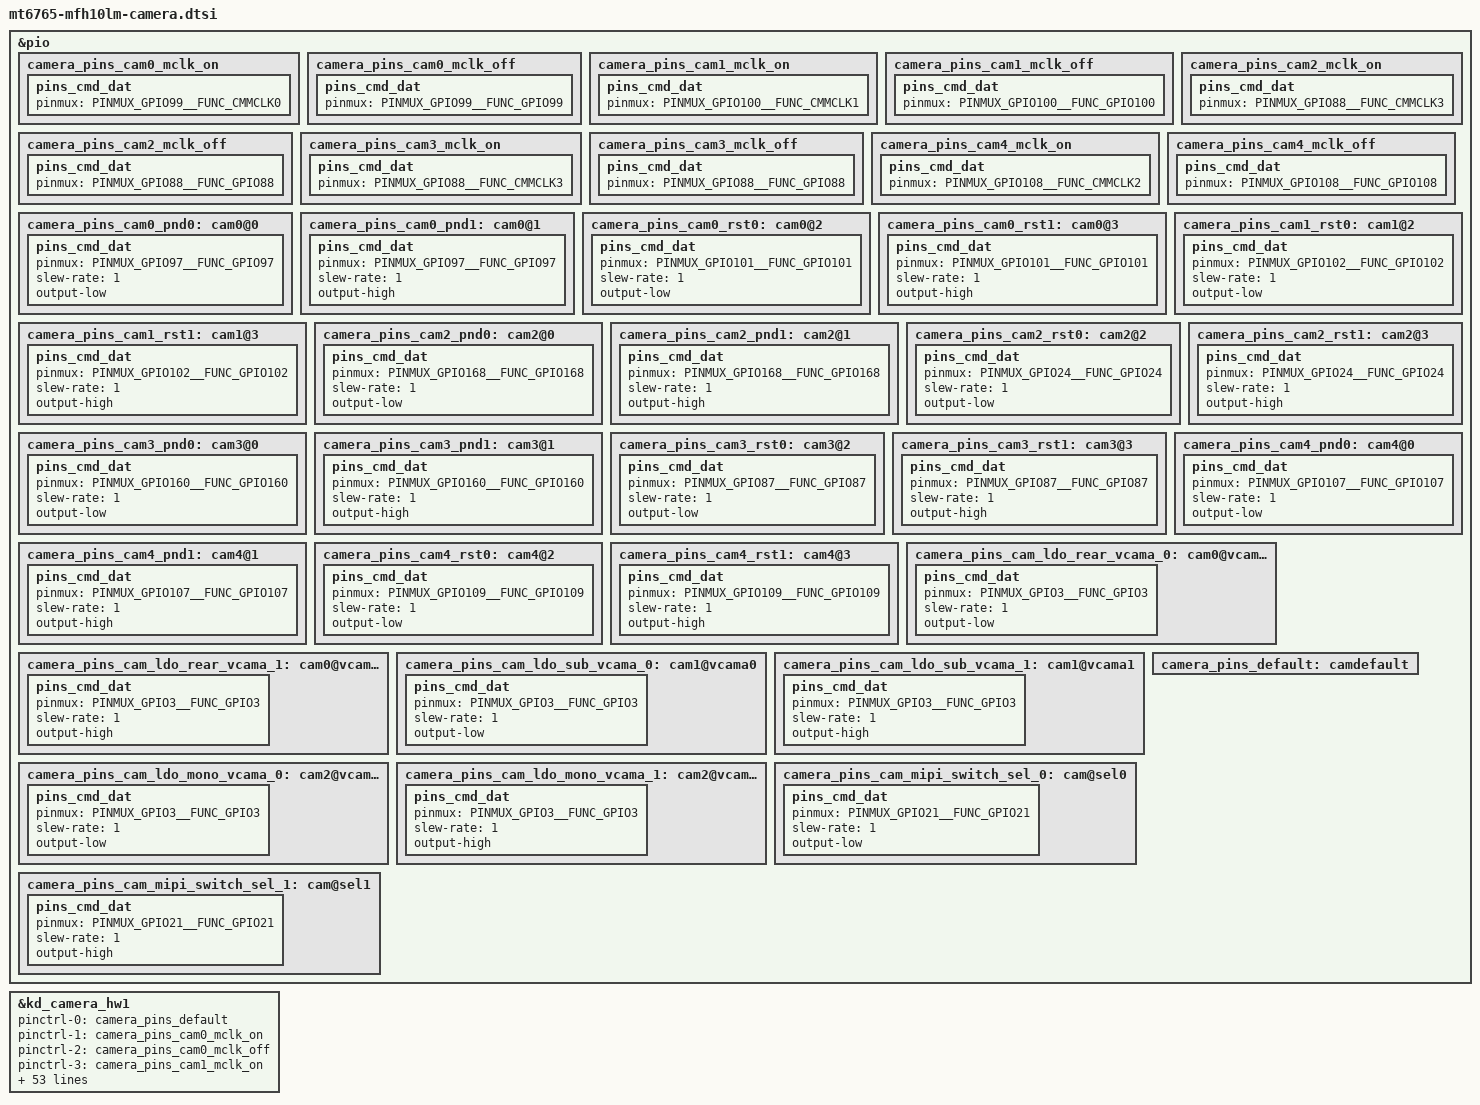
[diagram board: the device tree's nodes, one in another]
/*
 * Copyright (c) 2019 MediaTek Inc.
 *
 * This program is free software; you can redistribute it and/or modify
 * it under the terms of the GNU General Public License version 2 as
 * published by the Free Software Foundation.
 *
 * This program is distributed in the hope that it will be useful,
 * but WITHOUT ANY WARRANTY; without even the implied warranty of
 * MERCHANTABILITY or FITNESS FOR A PARTICULAR PURPOSE.  See the
 * GNU General Public License for more details.
 */
/* CAMERA GPIO standardization */
&pio {
	camera_pins_cam0_mclk_on: camera_pins_cam0_mclk_on {
		pins_cmd_dat {
			pinmux = <PINMUX_GPIO99__FUNC_CMMCLK0>;
		};
	};
	camera_pins_cam0_mclk_off: camera_pins_cam0_mclk_off {
		pins_cmd_dat {
			pinmux = <PINMUX_GPIO99__FUNC_GPIO99>;
		};
	};
	camera_pins_cam1_mclk_on: camera_pins_cam1_mclk_on {
		pins_cmd_dat {
			pinmux = <PINMUX_GPIO100__FUNC_CMMCLK1>;
		};
	};
	camera_pins_cam1_mclk_off: camera_pins_cam1_mclk_off {
		pins_cmd_dat {
			pinmux = <PINMUX_GPIO100__FUNC_GPIO100>;
		};
	};
	camera_pins_cam2_mclk_on: camera_pins_cam2_mclk_on {
		pins_cmd_dat {
			pinmux = <PINMUX_GPIO88__FUNC_CMMCLK3>;
		};
	};
	camera_pins_cam2_mclk_off: camera_pins_cam2_mclk_off {
		pins_cmd_dat {
			pinmux = <PINMUX_GPIO88__FUNC_GPIO88>;
		};
	};
	camera_pins_cam3_mclk_on: camera_pins_cam3_mclk_on {
		pins_cmd_dat {
			pinmux = <PINMUX_GPIO88__FUNC_CMMCLK3>;
		};
	};
	camera_pins_cam3_mclk_off: camera_pins_cam3_mclk_off {
		pins_cmd_dat {
			pinmux = <PINMUX_GPIO88__FUNC_GPIO88>;
		};
	};
	camera_pins_cam4_mclk_on: camera_pins_cam4_mclk_on {
		pins_cmd_dat {
			pinmux = <PINMUX_GPIO108__FUNC_CMMCLK2>;
		};
	};
	camera_pins_cam4_mclk_off: camera_pins_cam4_mclk_off {
		pins_cmd_dat {
			pinmux = <PINMUX_GPIO108__FUNC_GPIO108>;
		};
	};
	camera_pins_cam0_pnd0: cam0@0 {
		pins_cmd_dat {
			pinmux = <PINMUX_GPIO97__FUNC_GPIO97>;
			slew-rate = <1>;
			output-low;
		};
	};
	camera_pins_cam0_pnd1: cam0@1 {
		pins_cmd_dat {
			pinmux = <PINMUX_GPIO97__FUNC_GPIO97>;
			slew-rate = <1>;
			output-high;
		};
	};
	camera_pins_cam0_rst0: cam0@2 {
		pins_cmd_dat {
			pinmux = <PINMUX_GPIO101__FUNC_GPIO101>;
			slew-rate = <1>;
			output-low;
		};
	};
	camera_pins_cam0_rst1: cam0@3 {
		pins_cmd_dat {
			pinmux = <PINMUX_GPIO101__FUNC_GPIO101>;
			slew-rate = <1>;
			output-high;
		};
	};
	camera_pins_cam1_rst0: cam1@2 {
		pins_cmd_dat {
			pinmux = <PINMUX_GPIO102__FUNC_GPIO102>;
			slew-rate = <1>;
			output-low;
		};
	};
	camera_pins_cam1_rst1: cam1@3 {
		pins_cmd_dat {
			pinmux = <PINMUX_GPIO102__FUNC_GPIO102>;
			slew-rate = <1>;
			output-high;
		};
	};
	camera_pins_cam2_pnd0: cam2@0 {
		pins_cmd_dat {
			pinmux = <PINMUX_GPIO168__FUNC_GPIO168>;
			slew-rate = <1>;
			output-low;
		};
	};
	camera_pins_cam2_pnd1: cam2@1 {
		pins_cmd_dat {
			pinmux = <PINMUX_GPIO168__FUNC_GPIO168>;
			slew-rate = <1>;
			output-high;
		};
	};
	camera_pins_cam2_rst0: cam2@2 {
		pins_cmd_dat {
			pinmux = <PINMUX_GPIO24__FUNC_GPIO24>;
			slew-rate = <1>;
			output-low;
		};
	};
	camera_pins_cam2_rst1: cam2@3 {
		pins_cmd_dat {
			pinmux = <PINMUX_GPIO24__FUNC_GPIO24>;
			slew-rate = <1>;
			output-high;
		};
	};
	camera_pins_cam3_pnd0: cam3@0 {
		pins_cmd_dat {
			pinmux = <PINMUX_GPIO160__FUNC_GPIO160>;
			slew-rate = <1>;
			output-low;
		};
	};
	camera_pins_cam3_pnd1: cam3@1 {
		pins_cmd_dat {
			pinmux = <PINMUX_GPIO160__FUNC_GPIO160>;
			slew-rate = <1>;
			output-high;
		};
	};
	camera_pins_cam3_rst0: cam3@2 {
		pins_cmd_dat {
			pinmux = <PINMUX_GPIO87__FUNC_GPIO87>;
			slew-rate = <1>;
			output-low;
		};
	};
	camera_pins_cam3_rst1: cam3@3 {
		pins_cmd_dat {
			pinmux = <PINMUX_GPIO87__FUNC_GPIO87>;
			slew-rate = <1>;
			output-high;
		};
	};
	camera_pins_cam4_pnd0: cam4@0 {
		pins_cmd_dat {
			pinmux = <PINMUX_GPIO107__FUNC_GPIO107>;
			slew-rate = <1>;
			output-low;
		};
	};
	camera_pins_cam4_pnd1: cam4@1 {
		pins_cmd_dat {
			pinmux = <PINMUX_GPIO107__FUNC_GPIO107>;
			slew-rate = <1>;
			output-high;
		};
	};
	camera_pins_cam4_rst0: cam4@2 {
		pins_cmd_dat {
			pinmux = <PINMUX_GPIO109__FUNC_GPIO109>;
			slew-rate = <1>;
			output-low;
		};
	};
	camera_pins_cam4_rst1: cam4@3 {
		pins_cmd_dat {
			pinmux = <PINMUX_GPIO109__FUNC_GPIO109>;
			slew-rate = <1>;
			output-high;
		};
	};
	camera_pins_cam_ldo_rear_vcama_0: cam0@vcama0 {
		pins_cmd_dat {
			pinmux = <PINMUX_GPIO3__FUNC_GPIO3>;
			slew-rate = <1>;
			output-low;
		};
	};
	camera_pins_cam_ldo_rear_vcama_1: cam0@vcama1 {
		pins_cmd_dat {
			pinmux = <PINMUX_GPIO3__FUNC_GPIO3>;
			slew-rate = <1>;
			output-high;
		};
	};
	camera_pins_cam_ldo_sub_vcama_0: cam1@vcama0 {
		pins_cmd_dat {
			pinmux = <PINMUX_GPIO3__FUNC_GPIO3>;
			slew-rate = <1>;
			output-low;
		};
	};
	camera_pins_cam_ldo_sub_vcama_1: cam1@vcama1 {
		pins_cmd_dat {
			pinmux = <PINMUX_GPIO3__FUNC_GPIO3>;
			slew-rate = <1>;
			output-high;
		};
	};
	camera_pins_cam_ldo_mono_vcama_0: cam2@vcama0 {
		pins_cmd_dat {
			pinmux = <PINMUX_GPIO3__FUNC_GPIO3>;
			slew-rate = <1>;
			output-low;
		};
	};
	camera_pins_cam_ldo_mono_vcama_1: cam2@vcama1 {
		pins_cmd_dat {
			pinmux = <PINMUX_GPIO3__FUNC_GPIO3>;
			slew-rate = <1>;
			output-high;
		};
	};
	camera_pins_cam_mipi_switch_sel_0: cam@sel0 {
		pins_cmd_dat {
			pinmux = <PINMUX_GPIO21__FUNC_GPIO21>;
			slew-rate = <1>;
			output-low;
		};
	};
	camera_pins_cam_mipi_switch_sel_1: cam@sel1 {
		pins_cmd_dat {
			pinmux = <PINMUX_GPIO21__FUNC_GPIO21>;
			slew-rate = <1>;
			output-high;
		};
	};
	camera_pins_default: camdefault {
	};

};

&kd_camera_hw1 {
	pinctrl-names = "default",
			"cam0_mclk_on",
			"cam0_mclk_off",
			"cam1_mclk_on",
			"cam1_mclk_off",
			"cam2_mclk_on",
			"cam2_mclk_off",
			"cam3_mclk_on",
			"cam3_mclk_off",
			"cam4_mclk_on",
			"cam4_mclk_off",
			"cam0_pnd0",
			"cam0_pnd1",
			"cam0_rst0",
			"cam0_rst1",
			"cam1_rst0",
			"cam1_rst1",
			"cam2_pnd0",
			"cam2_pnd1",
			"cam2_rst0",
			"cam2_rst1",
			"cam3_pnd0",
			"cam3_pnd1",
			"cam3_rst0",
			"cam3_rst1",
			"cam4_pnd0",
			"cam4_pnd1",
			"cam4_rst0",
			"cam4_rst1",
			"cam0_vcama_on",
			"cam0_vcama_off",
			"cam1_vcama_on",
			"cam1_vcama_off",
			"cam2_vcama_on",
			"cam2_vcama_off",
			"cam_mipi_switch_sel_1",
			"cam_mipi_switch_sel_0";

	pinctrl-0 = <&camera_pins_default>;
	pinctrl-1 = <&camera_pins_cam0_mclk_on>;
	pinctrl-2 = <&camera_pins_cam0_mclk_off>;
	pinctrl-3 = <&camera_pins_cam1_mclk_on>;
	pinctrl-4 = <&camera_pins_cam1_mclk_off>;
	pinctrl-5 = <&camera_pins_cam2_mclk_on>;
	pinctrl-6 = <&camera_pins_cam2_mclk_off>;
	pinctrl-7 = <&camera_pins_cam3_mclk_on>;
	pinctrl-8 = <&camera_pins_cam3_mclk_off>;
	pinctrl-9 = <&camera_pins_cam4_mclk_on>;
	pinctrl-10 = <&camera_pins_cam4_mclk_off>;
	pinctrl-11 = <&camera_pins_cam0_pnd0>;
	pinctrl-12 = <&camera_pins_cam0_pnd1>;
	pinctrl-13 = <&camera_pins_cam0_rst0>;
	pinctrl-14 = <&camera_pins_cam0_rst1>;
	pinctrl-15 = <&camera_pins_cam1_rst0>;
	pinctrl-16 = <&camera_pins_cam1_rst1>;
	pinctrl-17 = <&camera_pins_cam2_pnd0>;
	pinctrl-18 = <&camera_pins_cam2_pnd1>;
	pinctrl-19 = <&camera_pins_cam2_rst0>;
	pinctrl-20 = <&camera_pins_cam2_rst1>;
	pinctrl-21 = <&camera_pins_cam3_pnd0>;
	pinctrl-22 = <&camera_pins_cam3_pnd1>;
	pinctrl-23 = <&camera_pins_cam3_rst0>;
	pinctrl-24 = <&camera_pins_cam3_rst1>;
	pinctrl-25 = <&camera_pins_cam4_pnd0>;
	pinctrl-26 = <&camera_pins_cam4_pnd1>;
	pinctrl-27 = <&camera_pins_cam4_rst0>;
	pinctrl-28 = <&camera_pins_cam4_rst1>;
	pinctrl-29 = <&camera_pins_cam_ldo_rear_vcama_1>;
	pinctrl-30 = <&camera_pins_cam_ldo_rear_vcama_0>;
	pinctrl-31 = <&camera_pins_cam_ldo_sub_vcama_1>;
	pinctrl-32 = <&camera_pins_cam_ldo_sub_vcama_0>;
	pinctrl-33 = <&camera_pins_cam_ldo_mono_vcama_1>;
	pinctrl-34 = <&camera_pins_cam_ldo_mono_vcama_0>;
	pinctrl-35 = <&camera_pins_cam_mipi_switch_sel_1>;
	pinctrl-36 = <&camera_pins_cam_mipi_switch_sel_0>;

	cam0_vcamd-supply = <&mt_pmic_vcamd_ldo_reg>;
	cam0_vcamio-supply = <&mt_pmic_vcamio_ldo_reg>;
	cam0_vcamaf-supply = <&mt_pmic_vldo28_ldo_reg>;
	cam1_vcamd-supply = <&mt_pmic_vcamd_ldo_reg>;
	cam1_vcamio-supply = <&mt_pmic_vcamio_ldo_reg>;
	cam2_vcamio-supply = <&mt_pmic_vcamio_ldo_reg>;
	cam3_vcama-supply = <&mt_pmic_vcama_ldo_reg>;
	cam3_vcamio-supply = <&mt_pmic_vcamio_ldo_reg>;
	cam4_vcamio-supply = <&mt_pmic_vcamio_ldo_reg>;
	cam4_vcama-supply = <&mt_pmic_vcama_ldo_reg>;

	cam0_enable_sensor = "fh10_hi1336_rear_sy_mipi_raw fh10_s5k3l6_rear_dc_mipi_raw";
	cam1_enable_sensor = "fh10_hi846_front_st_mipi_raw fh10_gc5035_front_lhyx_mipi_raw fh10_hi556_front_st_mipi_raw";
	cam2_enable_sensor = "fh10_gc02m1b_mono_lhyx_mipi_raw";
	cam3_enable_sensor = "fh10_gc02m1_micro_lhyx_mipi_raw fh10_ov02b10_micro_cxt_mipi_raw";
	cam4_enable_sensor = "fh10_gc02m1_depth_lhyx_mipi_raw fh10_ov02b10_depth_cxt_mipi_raw";

	status = "okay";

};
/* CAMERA GPIO end */
